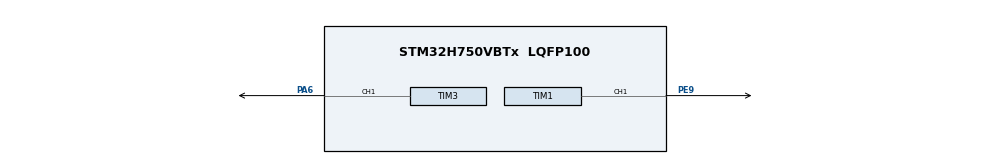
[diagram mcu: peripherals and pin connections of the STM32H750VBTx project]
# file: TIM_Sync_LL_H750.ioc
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Mcu.Family=STM32H7
Mcu.Name=STM32H750VBTx
Mcu.Package=LQFP100
NVIC.PriorityGroup=NVIC_PRIORITYGROUP_4
PA13\ (JTMS/SWDIO).Mode=Serial_Wire
PA13\ (JTMS/SWDIO).Signal=DEBUG_JTMS-SWDIO
PA14\ (JTCK/SWCLK).Mode=Serial_Wire
PA14\ (JTCK/SWCLK).Signal=DEBUG_JTCK-SWCLK
PA6.Signal=S_TIM3_CH1
PE9.Signal=S_TIM1_CH1
PH0-OSC_IN\ (PH0).Mode=HSE-External-Oscillator
PH0-OSC_IN\ (PH0).Signal=RCC_OSC_IN
PH1-OSC_OUT\ (PH1).Mode=HSE-External-Oscillator
PH1-OSC_OUT\ (PH1).Signal=RCC_OSC_OUT
ProjectManager.HeapSize=0x200
ProjectManager.StackSize=0x400
ProjectManager.TargetToolchain=STM32CubeIDE
RCC.ADCFreq_Value=50390625
RCC.APB1Freq_Value=120000000
RCC.APB2Freq_Value=120000000
RCC.APB3Freq_Value=120000000
RCC.APB4Freq_Value=120000000
RCC.CortexFreq_Value=240000000
RCC.DIVM1=25
RCC.DIVN1=480
RCC.HCLKFreq_Value=120000000
RCC.HPRE=RCC_HCLK_DIV2
RCC.PLLSourceVirtual=RCC_PLLSOURCE_HSE
RCC.SYSCLKFreq_VALUE=240000000
RCC.SYSCLKSource=RCC_SYSCLKSOURCE_PLLCLK
RCC.USBFreq_Value=240000000
SH.S_TIM1_CH1.0=TIM1_CH1,PWM Generation1 CH1
SH.S_TIM3_CH1.0=TIM3_CH1,PWM Generation1 CH1
TIM1.AutoReloadPreload=TIM_AUTORELOAD_PRELOAD_ENABLE
TIM1.Channel-PWM\ Generation1\ CH1=TIM_CHANNEL_1
TIM1.Period=999
TIM1.Prescaler=119
TIM1.Pulse-PWM\ Generation1\ CH1=500
TIM1.TIM_MasterOutputTrigger=TIM_TRGO_ENABLE
TIM3.AutoReloadPreload=TIM_AUTORELOAD_PRELOAD_ENABLE
TIM3.Channel-PWM\ Generation1\ CH1=TIM_CHANNEL_1
TIM3.Period=999
TIM3.Prescaler=119
TIM3.Pulse-PWM\ Generation1\ CH1=500
TIM3.TIM_MasterOutputTrigger=TIM_TRGO_RESET
VP_TIM1_VS_ClockSourceINT.Mode=Internal
VP_TIM3_VS_ClockSourceINT.Mode=Internal
VP_TIM3_VS_ClockSourceITR.Mode=TriggerSource_ITR0
VP_TIM3_VS_ControllerModeTrigger.Mode=Trigger Mode
board=custom

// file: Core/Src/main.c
/* USER CODE BEGIN Header */
/**
  ******************************************************************************
  * @file           : main.c
  * @brief          : Main program body
  ******************************************************************************
  * @attention
  *
  * Copyright (c) 2023 STMicroelectronics.
  * All rights reserved.
  *
  * This software is licensed under terms that can be found in the LICENSE file
  * in the root directory of this software component.
  * If no LICENSE file comes with this software, it is provided AS-IS.
  *
  ******************************************************************************
  */
/* USER CODE END Header */
#include "main.h"

void SystemClock_Config(void);
static void MX_GPIO_Init(void);
static void MX_TIM1_Init(void);
static void MX_TIM3_Init(void);

int main(void)
{

  /* MCU Configuration--------------------------------------------------------*/

  /* Reset of all peripherals, Initializes the Flash interface and the Systick. */
  LL_APB4_GRP1_EnableClock(LL_APB4_GRP1_PERIPH_SYSCFG);

  /* System interrupt init*/
  NVIC_SetPriorityGrouping(NVIC_PRIORITYGROUP_4);

  /* SysTick_IRQn interrupt configuration */
  NVIC_SetPriority(SysTick_IRQn, NVIC_EncodePriority(NVIC_GetPriorityGrouping(),15, 0));

  /* Configure the system clock */
  SystemClock_Config();

  /* Initialize all configured peripherals */
  MX_GPIO_Init();
  MX_TIM1_Init();
  MX_TIM3_Init();

  /* Infinite loop */
  /* USER CODE BEGIN WHILE */

  LL_TIM_CC_EnableChannel(TIM3, LL_TIM_CHANNEL_CH1); // 使能TIM3_CH1

//  LL_mDelay(233); // 这里不管设置多少延时，TIM3一定都是TIM1使能后才会开始工作

  LL_TIM_CC_EnableChannel(TIM1, LL_TIM_CHANNEL_CH1); // 使能TIM1_CH1
  LL_TIM_EnableAllOutputs(TIM1); // 对于高级定时器需要这一行PWM才会有输出
  LL_TIM_EnableCounter(TIM1); // 使能TIM1开始计数

  while (1)
  {
    /* USER CODE END WHILE */

  }
}

void SystemClock_Config(void)
{
  LL_FLASH_SetLatency(LL_FLASH_LATENCY_2);
  while(LL_FLASH_GetLatency()!= LL_FLASH_LATENCY_2)
  {
  }
  LL_PWR_ConfigSupply(LL_PWR_LDO_SUPPLY);
  LL_PWR_SetRegulVoltageScaling(LL_PWR_REGU_VOLTAGE_SCALE2);
  while (LL_PWR_IsActiveFlag_VOS() == 0)
  {
  }
  LL_RCC_HSE_Enable();

   /* Wait till HSE is ready */
  while(LL_RCC_HSE_IsReady() != 1)
  {

  }
  LL_RCC_PLL_SetSource(LL_RCC_PLLSOURCE_HSE);
  LL_RCC_PLL1P_Enable();
  LL_RCC_PLL1R_Enable();
  LL_RCC_PLL1_SetVCOInputRange(LL_RCC_PLLINPUTRANGE_1_2);
  LL_RCC_PLL1_SetVCOOutputRange(LL_RCC_PLLVCORANGE_WIDE);
  LL_RCC_PLL1_SetM(25);
  LL_RCC_PLL1_SetN(480);
  LL_RCC_PLL1_SetP(2);
  LL_RCC_PLL1_SetQ(2);
  LL_RCC_PLL1_SetR(2);
  LL_RCC_PLL1_Enable();

   /* Wait till PLL is ready */
  while(LL_RCC_PLL1_IsReady() != 1)
  {
  }

   /* Intermediate AHB prescaler 2 when target frequency clock is higher than 80 MHz */
   LL_RCC_SetAHBPrescaler(LL_RCC_AHB_DIV_2);

  LL_RCC_SetSysClkSource(LL_RCC_SYS_CLKSOURCE_PLL1);

   /* Wait till System clock is ready */
  while(LL_RCC_GetSysClkSource() != LL_RCC_SYS_CLKSOURCE_STATUS_PLL1)
  {

  }
  LL_RCC_SetSysPrescaler(LL_RCC_SYSCLK_DIV_1);
  LL_RCC_SetAHBPrescaler(LL_RCC_AHB_DIV_2);
  LL_RCC_SetAPB1Prescaler(LL_RCC_APB1_DIV_1);
  LL_RCC_SetAPB2Prescaler(LL_RCC_APB2_DIV_1);
  LL_RCC_SetAPB3Prescaler(LL_RCC_APB3_DIV_1);
  LL_RCC_SetAPB4Prescaler(LL_RCC_APB4_DIV_1);

  LL_Init1msTick(240000000);

  LL_SetSystemCoreClock(240000000);
}

static void MX_TIM1_Init(void)
{

  LL_TIM_InitTypeDef TIM_InitStruct = {0};
  LL_TIM_OC_InitTypeDef TIM_OC_InitStruct = {0};
  LL_TIM_BDTR_InitTypeDef TIM_BDTRInitStruct = {0};

  LL_GPIO_InitTypeDef GPIO_InitStruct = {0};

  /* Peripheral clock enable */
  LL_APB2_GRP1_EnableClock(LL_APB2_GRP1_PERIPH_TIM1);

  TIM_InitStruct.Prescaler = 119;
  TIM_InitStruct.CounterMode = LL_TIM_COUNTERMODE_UP;
  TIM_InitStruct.Autoreload = 999;
  TIM_InitStruct.ClockDivision = LL_TIM_CLOCKDIVISION_DIV1;
  TIM_InitStruct.RepetitionCounter = 0;
  LL_TIM_Init(TIM1, &TIM_InitStruct);
  LL_TIM_EnableARRPreload(TIM1);
  LL_TIM_SetClockSource(TIM1, LL_TIM_CLOCKSOURCE_INTERNAL);
  LL_TIM_OC_EnablePreload(TIM1, LL_TIM_CHANNEL_CH1);
  TIM_OC_InitStruct.OCMode = LL_TIM_OCMODE_PWM1;
  TIM_OC_InitStruct.OCState = LL_TIM_OCSTATE_DISABLE;
  TIM_OC_InitStruct.OCNState = LL_TIM_OCSTATE_DISABLE;
  TIM_OC_InitStruct.CompareValue = 500;
  TIM_OC_InitStruct.OCPolarity = LL_TIM_OCPOLARITY_HIGH;
  TIM_OC_InitStruct.OCNPolarity = LL_TIM_OCPOLARITY_HIGH;
  TIM_OC_InitStruct.OCIdleState = LL_TIM_OCIDLESTATE_LOW;
  TIM_OC_InitStruct.OCNIdleState = LL_TIM_OCIDLESTATE_LOW;
  LL_TIM_OC_Init(TIM1, LL_TIM_CHANNEL_CH1, &TIM_OC_InitStruct);
  LL_TIM_OC_DisableFast(TIM1, LL_TIM_CHANNEL_CH1);
  LL_TIM_SetTriggerOutput(TIM1, LL_TIM_TRGO_ENABLE);
  LL_TIM_SetTriggerOutput2(TIM1, LL_TIM_TRGO2_RESET);
  LL_TIM_DisableMasterSlaveMode(TIM1);
  TIM_BDTRInitStruct.OSSRState = LL_TIM_OSSR_DISABLE;
  TIM_BDTRInitStruct.OSSIState = LL_TIM_OSSI_DISABLE;
  TIM_BDTRInitStruct.LockLevel = LL_TIM_LOCKLEVEL_OFF;
  TIM_BDTRInitStruct.DeadTime = 0;
  TIM_BDTRInitStruct.BreakState = LL_TIM_BREAK_DISABLE;
  TIM_BDTRInitStruct.BreakPolarity = LL_TIM_BREAK_POLARITY_HIGH;
  TIM_BDTRInitStruct.BreakFilter = LL_TIM_BREAK_FILTER_FDIV1;
  TIM_BDTRInitStruct.Break2State = LL_TIM_BREAK2_DISABLE;
  TIM_BDTRInitStruct.Break2Polarity = LL_TIM_BREAK2_POLARITY_HIGH;
  TIM_BDTRInitStruct.Break2Filter = LL_TIM_BREAK2_FILTER_FDIV1;
  TIM_BDTRInitStruct.AutomaticOutput = LL_TIM_AUTOMATICOUTPUT_DISABLE;
  LL_TIM_BDTR_Init(TIM1, &TIM_BDTRInitStruct);
  LL_AHB4_GRP1_EnableClock(LL_AHB4_GRP1_PERIPH_GPIOE);
  /**TIM1 GPIO Configuration
  PE9   ------> TIM1_CH1
  */
  GPIO_InitStruct.Pin = LL_GPIO_PIN_9;
  GPIO_InitStruct.Mode = LL_GPIO_MODE_ALTERNATE;
  GPIO_InitStruct.Speed = LL_GPIO_SPEED_FREQ_LOW;
  GPIO_InitStruct.OutputType = LL_GPIO_OUTPUT_PUSHPULL;
  GPIO_InitStruct.Pull = LL_GPIO_PULL_NO;
  GPIO_InitStruct.Alternate = LL_GPIO_AF_1;
  LL_GPIO_Init(GPIOE, &GPIO_InitStruct);

}

static void MX_TIM3_Init(void)
{

  LL_TIM_InitTypeDef TIM_InitStruct = {0};
  LL_TIM_OC_InitTypeDef TIM_OC_InitStruct = {0};

  LL_GPIO_InitTypeDef GPIO_InitStruct = {0};

  /* Peripheral clock enable */
  LL_APB1_GRP1_EnableClock(LL_APB1_GRP1_PERIPH_TIM3);

  TIM_InitStruct.Prescaler = 119;
  TIM_InitStruct.CounterMode = LL_TIM_COUNTERMODE_UP;
  TIM_InitStruct.Autoreload = 999;
  TIM_InitStruct.ClockDivision = LL_TIM_CLOCKDIVISION_DIV1;
  LL_TIM_Init(TIM3, &TIM_InitStruct);
  LL_TIM_EnableARRPreload(TIM3);
  LL_TIM_SetClockSource(TIM3, LL_TIM_CLOCKSOURCE_INTERNAL);
  LL_TIM_OC_EnablePreload(TIM3, LL_TIM_CHANNEL_CH1);
  TIM_OC_InitStruct.OCMode = LL_TIM_OCMODE_PWM1;
  TIM_OC_InitStruct.OCState = LL_TIM_OCSTATE_DISABLE;
  TIM_OC_InitStruct.OCNState = LL_TIM_OCSTATE_DISABLE;
  TIM_OC_InitStruct.CompareValue = 500;
  TIM_OC_InitStruct.OCPolarity = LL_TIM_OCPOLARITY_HIGH;
  LL_TIM_OC_Init(TIM3, LL_TIM_CHANNEL_CH1, &TIM_OC_InitStruct);
  LL_TIM_OC_DisableFast(TIM3, LL_TIM_CHANNEL_CH1);
  LL_TIM_SetTriggerInput(TIM3, LL_TIM_TS_ITR0);
  LL_TIM_SetSlaveMode(TIM3, LL_TIM_SLAVEMODE_TRIGGER);
  LL_TIM_DisableIT_TRIG(TIM3);
  LL_TIM_DisableDMAReq_TRIG(TIM3);
  LL_TIM_SetTriggerOutput(TIM3, LL_TIM_TRGO_RESET);
  LL_TIM_DisableMasterSlaveMode(TIM3);
  LL_AHB4_GRP1_EnableClock(LL_AHB4_GRP1_PERIPH_GPIOA);
  /**TIM3 GPIO Configuration
  PA6   ------> TIM3_CH1
  */
  GPIO_InitStruct.Pin = LL_GPIO_PIN_6;
  GPIO_InitStruct.Mode = LL_GPIO_MODE_ALTERNATE;
  GPIO_InitStruct.Speed = LL_GPIO_SPEED_FREQ_LOW;
  GPIO_InitStruct.OutputType = LL_GPIO_OUTPUT_PUSHPULL;
  GPIO_InitStruct.Pull = LL_GPIO_PULL_NO;
  GPIO_InitStruct.Alternate = LL_GPIO_AF_2;
  LL_GPIO_Init(GPIOA, &GPIO_InitStruct);

}

static void MX_GPIO_Init(void)
{

  /* GPIO Ports Clock Enable */
  LL_AHB4_GRP1_EnableClock(LL_AHB4_GRP1_PERIPH_GPIOH);
  LL_AHB4_GRP1_EnableClock(LL_AHB4_GRP1_PERIPH_GPIOA);
  LL_AHB4_GRP1_EnableClock(LL_AHB4_GRP1_PERIPH_GPIOE);

}

void Error_Handler(void)
{
  __disable_irq();
  while (1)
  {
  }
}
